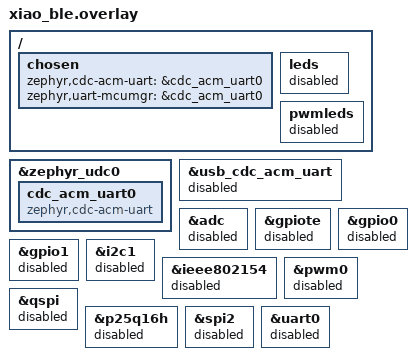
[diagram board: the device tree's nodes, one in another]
/ {
	chosen {
		zephyr,cdc-acm-uart = &cdc_acm_uart0;
		zephyr,uart-mcumgr = &cdc_acm_uart0;
	};

	leds {
		status = "disabled";
	};

	pwmleds {
		status = "disabled";
	};
};

&zephyr_udc0 {
	status = "okay";

	/*
	 * Define the CDC ACM UART node the `chosen` entries above reference. In an
	 * ESPHome build this comes from the generated app.overlay; the standalone
	 * migrator-base build (README.md) has no app.overlay, so define it here.
	 */
	cdc_acm_uart0: cdc_acm_uart0 {
		compatible = "zephyr,cdc-acm-uart";
	};
};

&usb_cdc_acm_uart {
	status = "disabled";
};

&adc {
	status = "disabled";
};

&gpiote {
	status = "disabled";
};

&gpio0 {
	status = "disabled";
};

&gpio1 {
	status = "disabled";
};

&i2c1 {
	status = "disabled";
};

&ieee802154 {
	status = "disabled";
};

&pwm0 {
	status = "disabled";
};

&qspi {
	status = "disabled";
};

&p25q16h {
	status = "disabled";
};

&spi2 {
	status = "disabled";
};

&uart0 {
	status = "disabled";
};
